# UPD70F3508 register map
Vendor: Renesas; Series: V850E2/Px4; File version: 1.0
CPU: other r0p0, little endian, no MPU, FPU, 4 interrupt priority bits
Registers are 8-bit, read-write, reset 0x0 unless marked. A register's access mark holds for its fields unless they carry their own. Offsets are from the block's base; [hi:lo] are bit positions; lines under a group give offsets from that group; {n}, {i} and the like mark numbered series.

## OSTM_CKSEL — OSTM Input Clock Select Function Registers (shared, applies to both OSTM instances)
Base 0xFF83F000
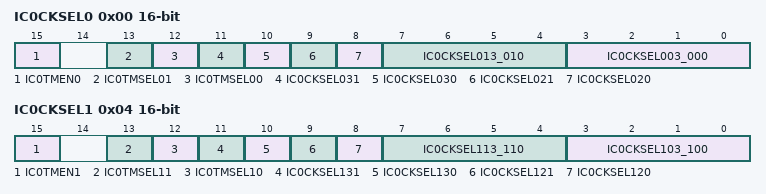
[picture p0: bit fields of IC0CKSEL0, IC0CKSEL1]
0x00 IC0CKSEL0 16-bit — OSTM Input Clock Select Function Register 0 (for OSTM0)
  [15] IC0TMEN0 — Counter-clock-enable signal select: 0=PCLK fixed high, 1=use selected timer signal
  [13] IC0TMSEL01 — Timer source selector (MSB): selects TAUA0/TAUA1/TAUJ0/TAUJ1 group
  [12] IC0TMSEL00 — Timer source selector (LSB): selects TAUA0/TAUA1/TAUJ0/TAUJ1 group
  [11] IC0CKSEL031 — TAUJ1 channel select MSB (bits 11:10 together select TAUJ1 ch0-3)
  [10] IC0CKSEL030 — TAUJ1 channel select LSB
  [9] IC0CKSEL021 — TAUJ0 channel select MSB (bits 9:8 together select TAUJ0 ch0-3)
  [8] IC0CKSEL020 — TAUJ0 channel select LSB
  [7:4] IC0CKSEL013_010 — TAUA1 timer channel select (bits 7:4, selects ch0-15)
  [3:0] IC0CKSEL003_000 — TAUA0 timer channel select (bits 3:0, selects ch0-15)
0x04 IC0CKSEL1 16-bit — OSTM Input Clock Select Function Register 1 (for OSTM1)
  [15] IC0TMEN1 — Counter-clock-enable signal select: 0=PCLK fixed high, 1=use selected timer signal
  [13] IC0TMSEL11 — Timer source selector (MSB): selects TAUA0/TAUA1/TAUJ0/TAUJ1 group
  [12] IC0TMSEL10 — Timer source selector (LSB): selects TAUA0/TAUA1/TAUJ0/TAUJ1 group
  [11] IC0CKSEL131 — TAUJ1 channel select MSB (bits 11:10 together select TAUJ1 ch0-3)
  [10] IC0CKSEL130 — TAUJ1 channel select LSB
  [9] IC0CKSEL121 — TAUJ0 channel select MSB (bits 9:8 together select TAUJ0 ch0-3)
  [8] IC0CKSEL120 — TAUJ0 channel select LSB
  [7:4] IC0CKSEL113_110 — TAUA1 timer channel select (bits 7:4, selects ch0-15)
  [3:0] IC0CKSEL103_100 — TAUA0 timer channel select (bits 3:0, selects ch0-15)

## BIST_AUX — SGA Error Pulse Control and Backup RAM Registers (merged: BIST_AUX, SGA_EPCTL)
Base 0xFF83F020
0x00 SGAEPCTL — SGA Error Pulse Control Register — selects timer source for SGA dynamic-mode operation
  [0] SGATMSL — Timer source select for SGA (0=TAUA1 ch15, 1=OSTM1)
{0x10+4i} BRAMDAT{i} 32-bit (i=0..3) — Backup RAM Register {i} — holds data [{32i+31}:{32i}] across self-diagnostic BIST

## TSC — Timing Supervision Counter registers — count, compare, and reload values for channels 0-5 (Table 9-31)
Base 0xFFFF5024
{0x0+0x10*i} TSCCNT{i} 32-bit (i=0..5) — Timing supervision counter {i} count value register
{0x4+0x10*i} TSCCMP{i} 32-bit (i=0..5) — Timing supervision counter {i} comparison value register
{0x8+0x10*i} TSCRLD{i} 32-bit (i=0..5) — Timing supervision counter {i} reload value register

## PPU — CPU Core Protection Peripheral Protection Unit violation registers (Table 9-30)
Base 0xFFFF5110
0x00 VPNECR 32-bit — Peripheral device protection NT state violation cause register (32-bit canonical; byte aliases VPNECRL/VPNECRLL/VPNECRLH also map here)
0x04 VPNADR 32-bit — Peripheral device protection NT state violation address register (32-bit canonical; byte/halfword aliases also map here)
0x08 VPNTID 32-bit — Peripheral device protection NT state violation task ID register (32-bit canonical; byte/halfword aliases also map here)
0x10 VPTECR 32-bit — Peripheral device protection T state violation cause register (32-bit canonical; byte aliases also map here)
0x14 VPTADR 32-bit — Peripheral device protection T state violation address register (32-bit canonical; byte/halfword aliases also map here)
0x18 VPTTID 32-bit — Peripheral device protection T state violation task ID register (32-bit canonical; byte/halfword aliases also map here)

## CPUREG — CPU Processor Element Identifier Register (Section 3.6)
Base 0xFFFF6490
0x00 PEID 16-bit ro reset 0x1 — Processor Element Identifier Register — returns the processor-element identifier of the last accessing CPU
  [15:0] PEID — Processor element ID; always reads as 0001H
